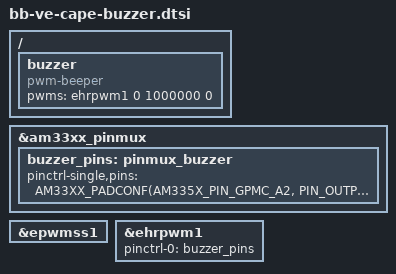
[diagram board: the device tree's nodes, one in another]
/ {
	buzzer {
		compatible = "pwm-beeper";
		pwms = <&ehrpwm1 0 1000000 0>;
	};
};

&am33xx_pinmux {
	buzzer_pins: pinmux_buzzer {
		pinctrl-single,pins = <
			AM33XX_PADCONF(AM335X_PIN_GPMC_A2, PIN_OUTPUT, MUX_MODE6)
		>;
	};
};

&epwmss1 {
	status = "okay";
};

&ehrpwm1 {
	status = "okay";
	pinctrl-names = "default";
	pinctrl-0 = <&buzzer_pins>;
};
